# STM32L4x2 register map
File version: 2.3
CPU: CM4 r0p1, little endian, MPU, FPU, 4 interrupt priority bits
Registers are 32-bit, read-write, reset 0x0 unless marked. A register's access mark holds for its fields unless they carry their own. Offsets are from the block's base; [hi:lo] are bit positions; {n}, {i} and the like mark numbered series.

## SYSCFG — System configuration controller
Base 0x40010000
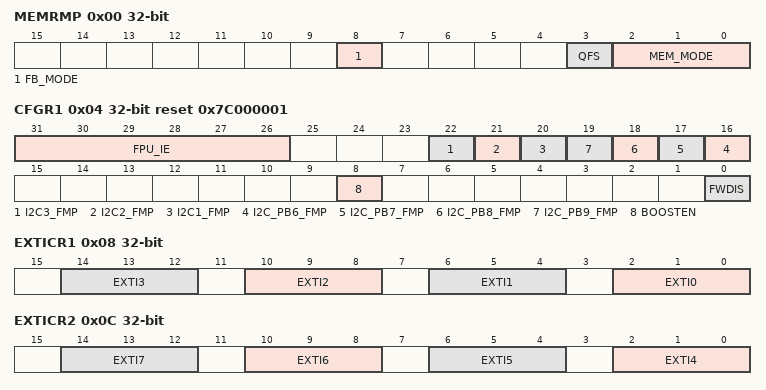
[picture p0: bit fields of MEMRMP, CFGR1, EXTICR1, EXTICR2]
0x00 MEMRMP — memory remap register
  [8] FB_MODE — Flash Bank mode selection
  [3] QFS — QUADSPI memory mapping swap
  [2:0] MEM_MODE — Memory mapping selection
0x04 CFGR1 reset 0x7C000001 — configuration register 1
  [31:26] FPU_IE — Floating Point Unit interrupts enable bits
  [22] I2C3_FMP — I2C3 Fast-mode Plus driving capability activation
  [21] I2C2_FMP — I2C2 Fast-mode Plus driving capability activation
  [20] I2C1_FMP — I2C1 Fast-mode Plus driving capability activation
  [n+10] I2C_PB{n}_FMP (n=6..9) — Fast-mode Plus (Fm+) driving capability activation on PB{n}
  [8] BOOSTEN — I/O analog switch voltage booster enable
  [0] FWDIS — Firewall disable
0x08 EXTICR1 — external interrupt configuration register 1
  [4n+2:4n] EXTI{n} (n=0..3) — EXTI {n} configuration bits
0x0C EXTICR2 — external interrupt configuration register 2
  [4n-14:4n-16] EXTI{n} (n=4..7) — EXTI {n} configuration bits
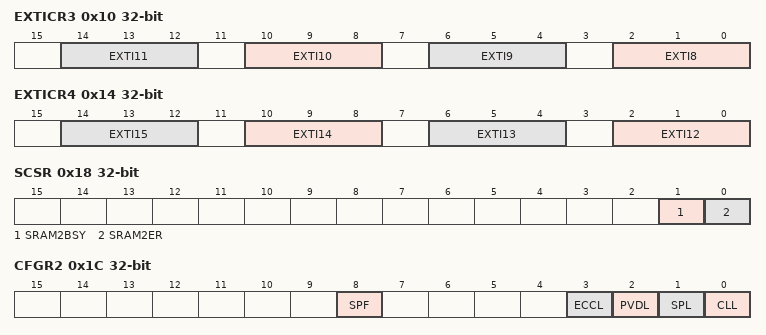
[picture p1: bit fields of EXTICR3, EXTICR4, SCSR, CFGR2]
0x10 EXTICR3 — external interrupt configuration register 3
  [4n-30:4n-32] EXTI{n} (n=8..11) — EXTI {n} configuration bits
0x14 EXTICR4 — external interrupt configuration register 4
  [4n-46:4n-48] EXTI{n} (n=12..15) — EXTI{n} configuration bits
0x18 SCSR access per field
  [1] SRAM2BSY ro — SRAM2 busy by erase operation
  [0] SRAM2ER rw — SRAM2 Erase
0x1C CFGR2 access per field
  [8] SPF rw — SRAM2 parity error flag
  [3] ECCL wo — ECC Lock
  [2] PVDL wo — PVD lock enable bit
  [1] SPL wo — SRAM2 parity lock bit
  [0] CLL wo — OCKUP (Hardfault) output enable bit
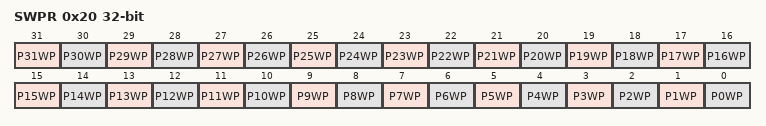
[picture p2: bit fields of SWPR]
0x20 SWPR wo
  [31] P31WP — SRAM2 page 31 write protection
  [n] P{n}WP (n=0..30)
0x24 SKR wo
  [7:0] KEY — SRAM2 write protection key for software erase

## RNG — Random number generator
Base 0x50060800
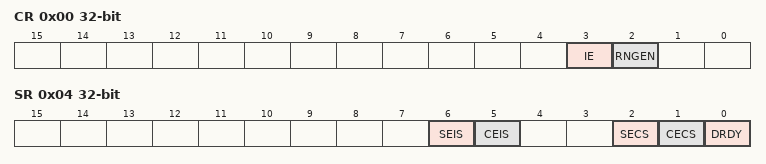
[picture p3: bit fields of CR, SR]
0x00 CR — control register
  [3] IE — Interrupt enable
    0=Disabled (RNG interrupt is disabled); 1=Enabled (RNG interrupt is enabled)
  [2] RNGEN — Random number generator enable
    0=Disabled (Random number generator is disabled); 1=Enabled (Random number generator is enabled)
0x04 SR access per field — status register
  [6] SEIS rw write-0-clears — Seed error interrupt status
    on write: 0=Clear flag | on read: 0=No faulty sequence detected; 1=Fault (At least one faulty sequence has been detected. See **SECS** bit description for details. An interrupt is pending if IE = 1 in the RNG_CR register.)
  [5] CEIS rw write-0-clears — Clock error interrupt status
    on write: 0=Clear flag | on read: 0=Correct (The RNG clock is correct); 1=Slow (The RNG has been detected too slow An interrupt is pending if IE = 1 in the RNG_CR register)
  [2] SECS ro — Seed error current status
    0=No faulty sequence has currently been detected. If the SEIS bit is set, this means that a faulty sequence was detected and the situation has been recovered.; 1=Fault (At least one faulty sequence has been detected - see ref manual for details)
  [1] CECS ro — Clock error current status
    0=Correct (The RNG clock is correct. If the CEIS bit is set, this means that a slow clock was detected and the situation has been recovered.); 1=Slow (The RNG clock is too slow)
  [0] DRDY ro — Data ready
    0=Invalid (The RNG_DR register is not yet valid, no random data is available); 1=Valid (The RNG_DR register contains valid random data. Once the RNG_DR register has been read, this bit returns to 0 until a new random value is generated.)
0x08 DR ro — data register
  [31:0] RNDATA — Random data

## GPIOA — General-purpose I/Os
Base 0x48000000
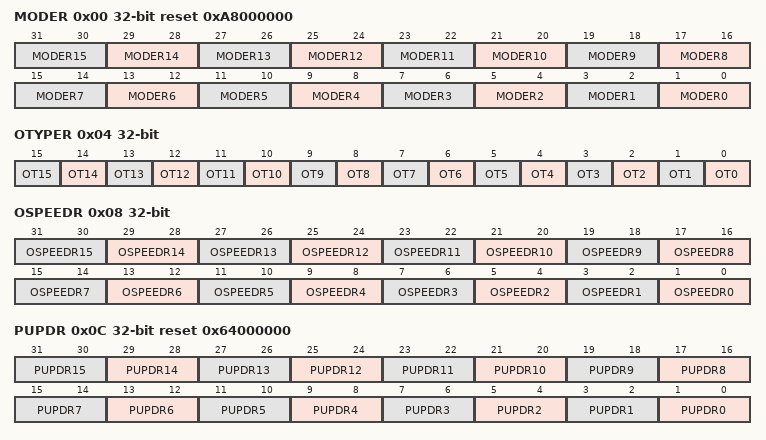
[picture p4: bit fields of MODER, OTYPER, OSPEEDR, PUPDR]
0x00 MODER reset 0xA8000000 — GPIO port mode register
  [2n+1:2n] MODER{n} (n=0..15) — Port x configuration pin {n}
    0=Input mode (reset state); 1=Output (General purpose output mode); 2=Alternate function mode; 3=Analog mode
0x04 OTYPER — GPIO port output type register
  [n] OT{n} (n=0..15) — Port x configuration pin {n}
    0=PushPull (Output push-pull (reset state)); 1=OpenDrain (Output open-drain)
0x08 OSPEEDR — GPIO port output speed register
  [2n+1:2n] OSPEEDR{n} (n=0..15) — Port x configuration pin {n}
    0=LowSpeed; 1=MediumSpeed; 2=HighSpeed; 3=VeryHighSpeed
0x0C PUPDR reset 0x64000000 — GPIO port pull-up/pull-down register
  [2n+1:2n] PUPDR{n} (n=0..15) — Port x configuration pin {n}
    0=Floating (No pull-up, pull-down); 1=PullUp; 2=PullDown
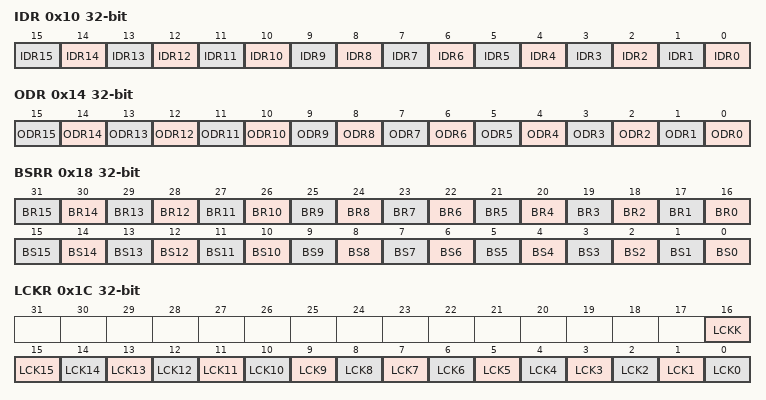
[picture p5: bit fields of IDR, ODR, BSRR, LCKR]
0x10 IDR ro — GPIO port input data register
  [n] IDR{n} (n=0..15) — Port input data pin {n}
    0=Low (Input is logic low); 1=High (Input is logic high)
0x14 ODR — GPIO port output data register
  [n] ODR{n} (n=0..15) — Port output data pin {n}
    0=Low (Set output to logic low); 1=High (Set output to logic high)
0x18 BSRR wo — GPIO port bit set/reset register
  [n+16] BR{n} (n=0..15) — Port x reset pin {n}
    1=Resets the corresponding ODRx bit
  [n] BS{n} (n=0..15) — Port x set pin {n}
    1=Set (Sets the corresponding ODRx bit)
0x1C LCKR — GPIO port configuration lock register
  [16] LCKK — Port x lock bit y (y= 0..15)
    0=NotActive (Port configuration lock key not active); 1=Active (Port configuration lock key active)
  [n] LCK{n} (n=0..15) — Port x lock pin {n}
    0=Unlocked (Port configuration not locked); 1=Locked (Port configuration locked)
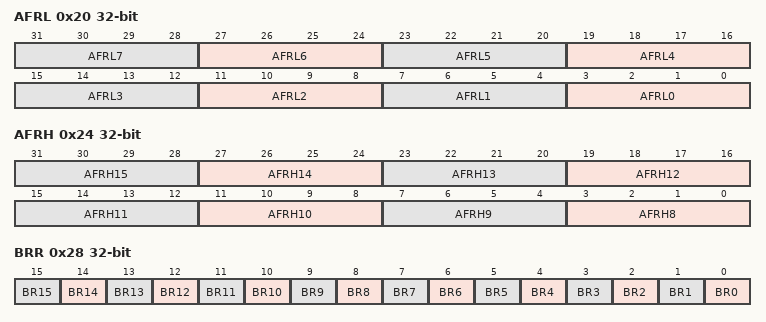
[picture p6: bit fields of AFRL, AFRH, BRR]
0x20 AFRL — GPIO alternate function low register
  [3:0] AFR{x} (x=L0,L1,L2,L3,L4,L5,L6,L7; step 4) — Alternate function selection for port x bit y (y = 0..7)
    {v}=AF{v} (v=0..15)
0x24 AFRH — GPIO alternate function high register
  [3:0] AFR{x} (x=H8,H9,H10,H11,H12,H13,H14,H15; step 4) — Alternate function selection for port x bit y (y = 8..15)
    {v}=AF{v} (v=0..15)
0x28 BRR access not given — GPIO port bit reset register
  [n] BR{n} (n=0..15) — Port x reset pin {n}
    on write: 0=No action on the corresponding ODx bit; 1=Reset the ODx bit

## GPIOB — General-purpose I/Os
Base 0x48000400
Registers as GPIOA; these are added or differ:
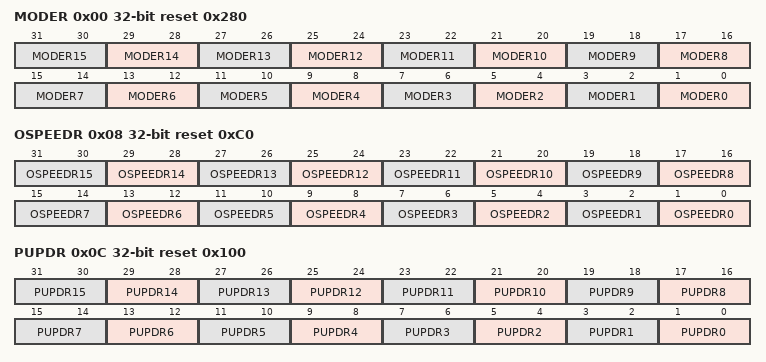
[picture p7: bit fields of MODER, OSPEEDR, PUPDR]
0x00 MODER reset 0x280 — GPIO port mode register
  [2n+1:2n] MODER{n} (n=0..15) — Port x configuration pin {n}
    0=Input mode (reset state); 1=Output (General purpose output mode); 2=Alternate function mode; 3=Analog mode
0x08 OSPEEDR reset 0xC0 — GPIO port output speed register
  [2n+1:2n] OSPEEDR{n} (n=0..15) — Port x configuration pin {n}
    0=LowSpeed; 1=MediumSpeed; 2=HighSpeed; 3=VeryHighSpeed
0x0C PUPDR reset 0x100 — GPIO port pull-up/pull-down register
  [2n+1:2n] PUPDR{n} (n=0..15) — Port x configuration pin {n}
    0=Floating (No pull-up, pull-down); 1=PullUp; 2=PullDown

## GPIOC — General-purpose I/Os
Base 0x48000800
Same registers: GPIOD 0x48000C00, GPIOE 0x48001000, GPIOH 0x48001C00
Registers as GPIOA; these are added or differ:
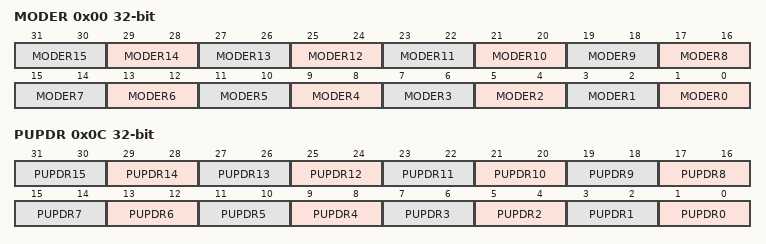
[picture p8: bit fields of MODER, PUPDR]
0x00 MODER — GPIO port mode register
  [2n+1:2n] MODER{n} (n=0..15) — Port x configuration pin {n}
    0=Input mode (reset state); 1=Output (General purpose output mode); 2=Alternate function mode; 3=Analog mode
0x0C PUPDR — GPIO port pull-up/pull-down register
  [2n+1:2n] PUPDR{n} (n=0..15) — Port x configuration pin {n}
    0=Floating (No pull-up, pull-down); 1=PullUp; 2=PullDown
